# HDSC_HC32L130F8UA register map
Vendor: HDSC Co.Ltd; Series: ARMCM0P; File version: 1.2
CPU: CM0 r0p0, little endian, no MPU, no FPU, 3 interrupt priority bits
Registers are 32-bit, read-write, reset 0x0 unless marked. A register's access mark holds for its fields unless they carry their own. Offsets are from the block's base; [hi:lo] are bit positions; {n}, {i} and the like mark numbered series; 'fields as' and 'values as' point back to an identical list.

## TIM0_MODE23
Base 0x40000C00; alternate view of TIM0_MODE0
0x00 ARR
  [15:0] ARR
0x04 CNT
  [15:0] CNT
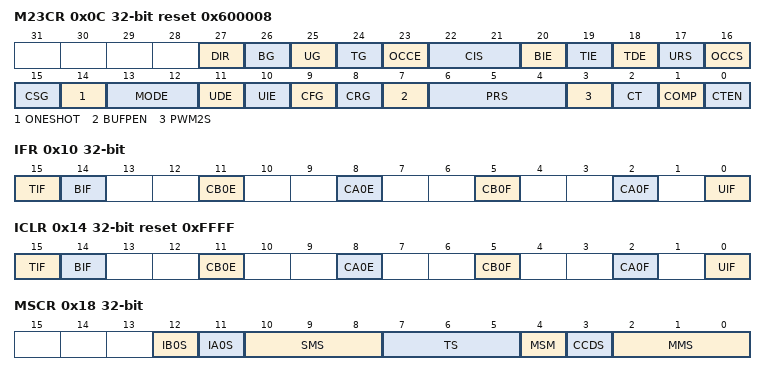
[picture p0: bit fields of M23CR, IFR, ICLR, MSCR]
0x0C M23CR reset 0x600008
  [27] DIR, [26] BG wo, [25] UG wo, [24] TG wo, [23] OCCE, [22:21] CIS, [20] BIE, [19] TIE, [18] TDE, [17] URS, [16] OCCS, [15] CSG, [14] ONESHOT, [13:12] MODE, [11] UDE, [10] UIE, [9] CFG, [8] CRG, [7] BUFPEN, [6:4] PRS, [3] PWM2S, [2] CT, [1] COMP, [0] CTEN
0x10 IFR ro
  [15] TIF, [14] BIF, [11] CB0E, [8] CA0E, [5] CB0F, [2] CA0F, [0] UIF
0x14 ICLR wo reset 0xFFFF
  [15] TIF, [14] BIF, [11] CB0E, [8] CA0E, [5] CB0F, [2] CA0F, [0] UIF
0x18 MSCR
  [12] IB0S, [11] IA0S, [10:8] SMS, [7:5] TS, [4] MSM, [3] CCDS, [2:0] MMS
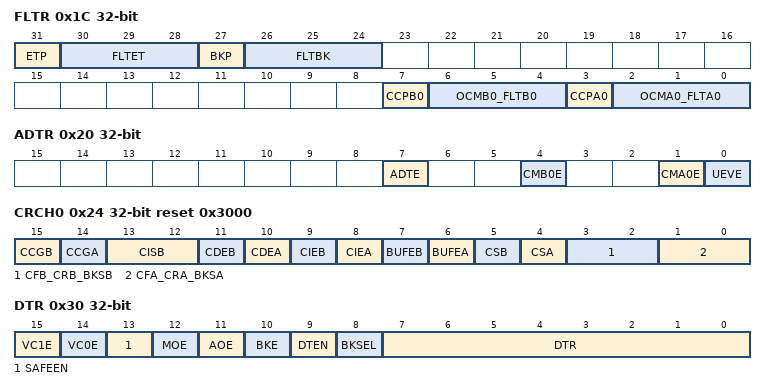
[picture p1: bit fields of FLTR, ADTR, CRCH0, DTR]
0x1C FLTR
  [31] ETP, [30:28] FLTET, [27] BKP, [26:24] FLTBK, [7] CCPB0, [6:4] OCMB0_FLTB0, [3] CCPA0, [2:0] OCMA0_FLTA0
0x20 ADTR
  [7] ADTE, [4] CMB0E, [1] CMA0E, [0] UEVE
0x24 CRCH0 reset 0x3000
  [15] CCGB, [14] CCGA, [13:12] CISB, [11] CDEB, [10] CDEA, [9] CIEB, [8] CIEA, [7] BUFEB, [6] BUFEA, [5] CSB, [4] CSA, [3:2] CFB_CRB_BKSB, [1:0] CFA_CRA_BKSA
0x30 DTR
  [15] VC1E, [14] VC0E, [13] SAFEEN, [12] MOE, [11] AOE, [10] BKE, [9] DTEN, [8] BKSEL, [7:0] DTR
0x34 RCR
  [7:0] RCR
0x38 ARRDM
  [15:0] ARRDM
0x3C CCR0A
  [15:0] CCR0A
0x40 CCR0B
  [15:0] CCR0B

## TIM1_MODE23
Base 0x40000D00; alternate view of TIM1_MODE0
Registers as TIM0_MODE23.

## TIM2_MODE23
Base 0x40000E00; alternate view of TIM2_MODE0
Registers as TIM0_MODE23.

## TIM3_MODE23
Base 0x40005800; alternate view of TIM3_MODE0
0x00 ARR
  [15:0] ARR
0x04 CNT
  [15:0] CNT
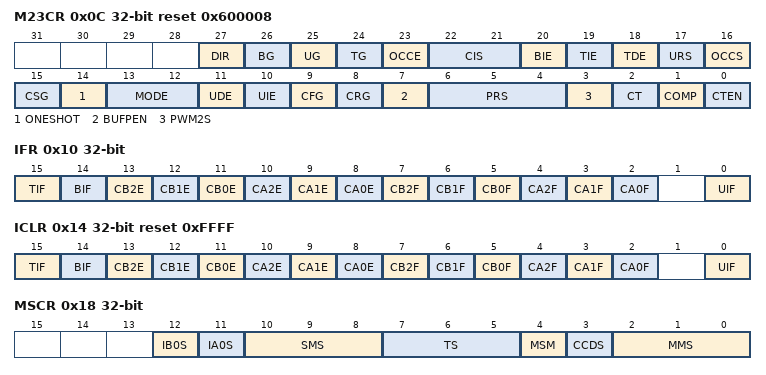
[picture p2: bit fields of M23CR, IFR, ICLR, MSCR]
0x0C M23CR reset 0x600008
  [27] DIR, [26] BG wo, [25] UG wo, [24] TG wo, [23] OCCE, [22:21] CIS, [20] BIE, [19] TIE, [18] TDE, [17] URS, [16] OCCS, [15] CSG, [14] ONESHOT, [13:12] MODE, [11] UDE, [10] UIE, [9] CFG, [8] CRG, [7] BUFPEN, [6:4] PRS, [3] PWM2S, [2] CT, [1] COMP, [0] CTEN
0x10 IFR ro
  [15] TIF, [14] BIF, [13] CB2E, [12] CB1E, [11] CB0E, [10] CA2E, [9] CA1E, [8] CA0E, [7] CB2F, [6] CB1F, [5] CB0F, [4] CA2F, [3] CA1F, [2] CA0F, [0] UIF
0x14 ICLR wo reset 0xFFFF
  fields as IFR
0x18 MSCR
  [12] IB0S, [11] IA0S, [10:8] SMS, [7:5] TS, [4] MSM, [3] CCDS, [2:0] MMS
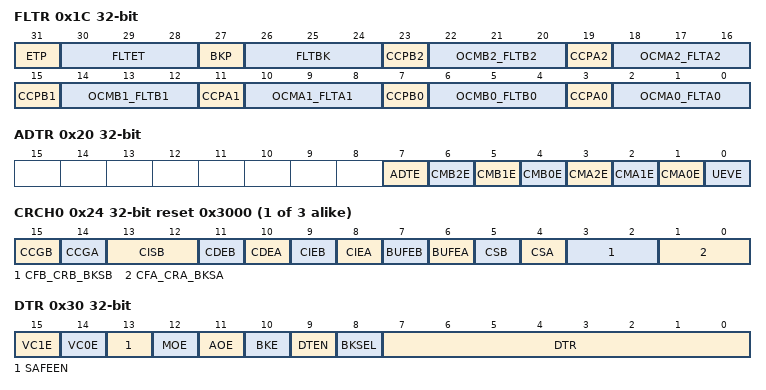
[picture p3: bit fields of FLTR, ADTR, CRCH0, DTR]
0x1C FLTR
  [31] ETP, [30:28] FLTET, [27] BKP, [26:24] FLTBK, [23] CCPB2, [22:20] OCMB2_FLTB2, [19] CCPA2, [18:16] OCMA2_FLTA2, [15] CCPB1, [14:12] OCMB1_FLTB1, [11] CCPA1, [10:8] OCMA1_FLTA1, [7] CCPB0, [6:4] OCMB0_FLTB0, [3] CCPA0, [2:0] OCMA0_FLTA0
0x20 ADTR
  [7] ADTE, [6] CMB2E, [5] CMB1E, [4] CMB0E, [3] CMA2E, [2] CMA1E, [1] CMA0E, [0] UEVE
{0x24+4i} CRCH{i} reset 0x3000 (i=0..2)
  [15] CCGB, [14] CCGA, [13:12] CISB, [11] CDEB, [10] CDEA, [9] CIEB, [8] CIEA, [7] BUFEB, [6] BUFEA, [5] CSB, [4] CSA, [3:2] CFB_CRB_BKSB, [1:0] CFA_CRA_BKSA
0x30 DTR
  [15] VC1E, [14] VC0E, [13] SAFEEN, [12] MOE, [11] AOE, [10] BKE, [9] DTEN, [8] BKSEL, [7:0] DTR
0x34 RCR
  [7:0] RCR
0x38 ARRDM
  [15:0] ARRDM
{0x3C+8i} CCR{i}A (i=0..2)
  [15:0] CCR{i}A
{0x40+8i} CCR{i}B (i=0..2)
  [15:0] CCR{i}B

## TIM4
Base 0x40003000
Same registers: TIM5 0x40003400, TIM6 0x40003800
0x00 CNTER
  [15:0] CNT
0x04 PERAR reset 0xFFFF
  [15:0] PERA
0x08 PERBR reset 0xFFFF
  [15:0] PERB
0x10 GCMAR reset 0xFFFF
  [15:0] GCMA
0x14 GCMBR reset 0xFFFF
  [15:0] GCMB
0x18 GCMCR reset 0xFFFF
  [15:0] GCMC
0x1C GCMDR reset 0xFFFF
  [15:0] GCMD
0x28 SCMAR reset 0xFFFF
  [15:0] SCMA
0x2C SCMBR reset 0xFFFF
  [15:0] SCMB
0x40 DTUAR reset 0xFFFF
  [15:0] DTUA
0x44 DTDAR reset 0xFFFF
  [15:0] DTDA
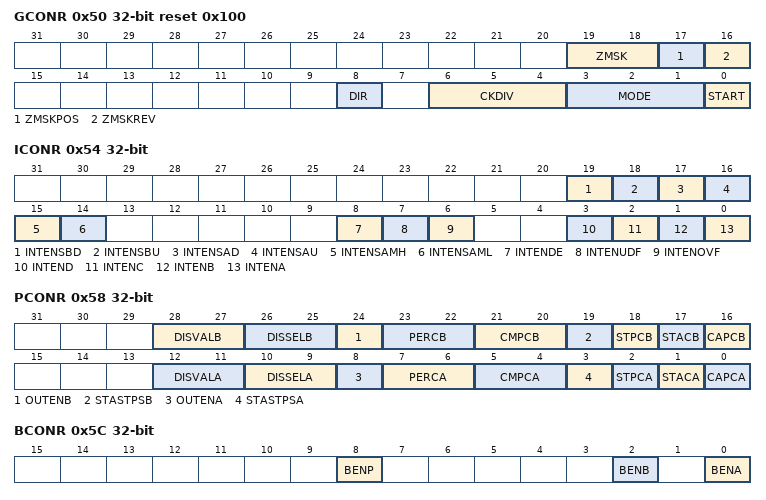
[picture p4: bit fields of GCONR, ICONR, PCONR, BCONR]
0x50 GCONR reset 0x100
  [19:18] ZMSK, [17] ZMSKPOS, [16] ZMSKREV, [8] DIR, [6:4] CKDIV, [3:1] MODE, [0] START
0x54 ICONR
  [19] INTENSBD, [18] INTENSBU, [17] INTENSAD, [16] INTENSAU, [15] INTENSAMH, [14] INTENSAML, [8] INTENDE, [7] INTENUDF, [6] INTENOVF, [3] INTEND, [2] INTENC, [1] INTENB, [0] INTENA
0x58 PCONR
  [28:27] DISVALB, [26:25] DISSELB, [24] OUTENB, [23:22] PERCB, [21:20] CMPCB, [19] STASTPSB, [18] STPCB, [17] STACB, [16] CAPCB, [12:11] DISVALA, [10:9] DISSELA, [8] OUTENA, [7:6] PERCA, [5:4] CMPCA, [3] STASTPSA, [2] STPCA, [1] STACA, [0] CAPCA
0x5C BCONR
  [8] BENP, [2] BENB, [0] BENA
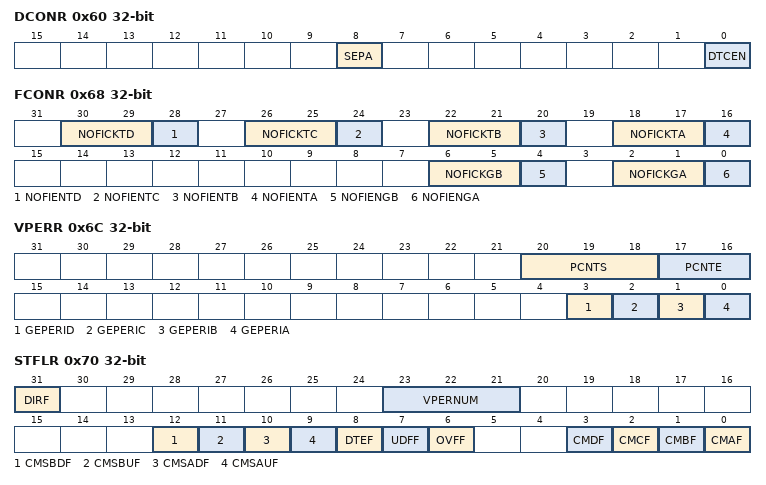
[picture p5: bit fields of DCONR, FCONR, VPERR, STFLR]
0x60 DCONR
  [8] SEPA, [0] DTCEN
0x68 FCONR
  [30:29] NOFICKTD, [28] NOFIENTD, [26:25] NOFICKTC, [24] NOFIENTC, [22:21] NOFICKTB, [20] NOFIENTB, [18:17] NOFICKTA, [16] NOFIENTA, [6:5] NOFICKGB, [4] NOFIENGB, [2:1] NOFICKGA, [0] NOFIENGA
0x6C VPERR
  [20:18] PCNTS, [17:16] PCNTE, [3] GEPERID, [2] GEPERIC, [1] GEPERIB, [0] GEPERIA
0x70 STFLR (reset mask 0x81C01FCF)
  [31] DIRF ro, [23:21] VPERNUM ro, [12] CMSBDF, [11] CMSBUF, [10] CMSADF, [9] CMSAUF, [8] DTEF, [7] UDFF, [6] OVFF, [3] CMDF, [2] CMCF, [1] CMBF, [0] CMAF
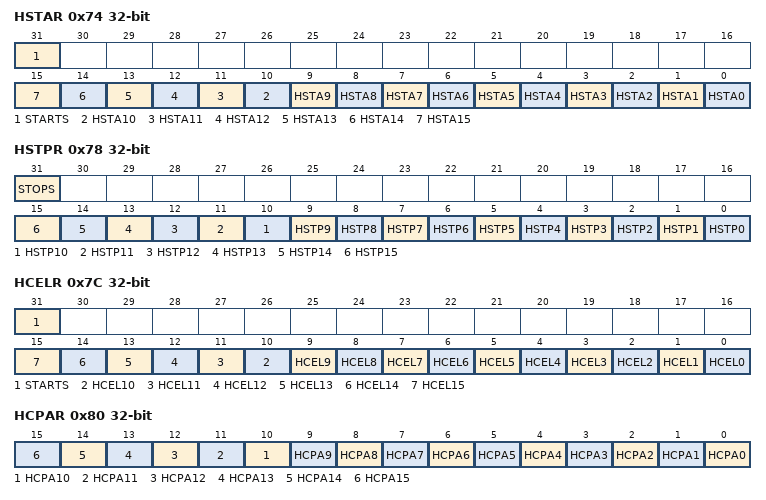
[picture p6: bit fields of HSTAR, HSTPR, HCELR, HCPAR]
0x74 HSTAR
  [31] STARTS, [n] HSTA{n} (n=0..15)
0x78 HSTPR
  [31] STOPS, [n] HSTP{n} (n=0..15)
0x7C HCELR
  [31] STARTS, [n] HCEL{n} (n=0..15)
0x80 HCPAR
  [n] HCPA{n} (n=0..15)
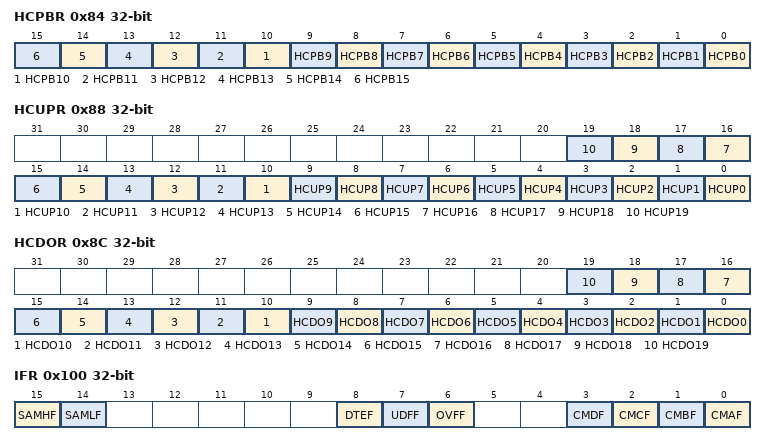
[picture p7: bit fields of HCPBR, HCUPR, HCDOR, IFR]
0x84 HCPBR
  [n] HCPB{n} (n=0..15)
0x88 HCUPR
  [n] HCUP{n} (n=0..19)
0x8C HCDOR
  [n] HCDO{n} (n=0..19)
0x100 IFR ro
  [15] SAMHF, [14] SAMLF, [8] DTEF, [7] UDFF, [6] OVFF, [3] CMDF, [2] CMCF, [1] CMBF, [0] CMAF
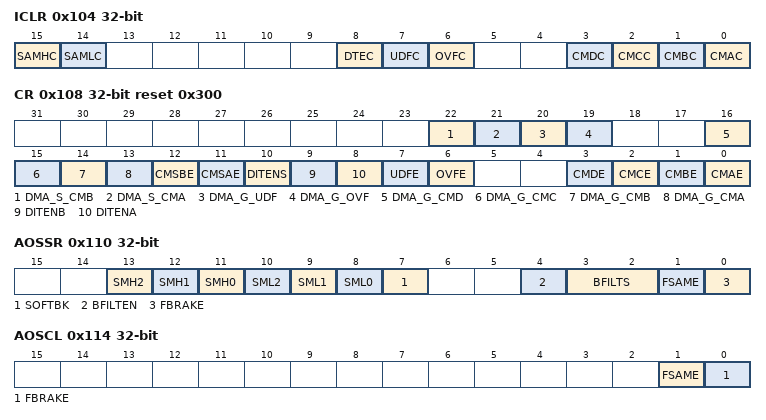
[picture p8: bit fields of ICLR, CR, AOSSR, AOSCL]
0x104 ICLR wo
  [15] SAMHC, [14] SAMLC, [8] DTEC, [7] UDFC, [6] OVFC, [3] CMDC, [2] CMCC, [1] CMBC, [0] CMAC
0x108 CR reset 0x300
  [22] DMA_S_CMB, [21] DMA_S_CMA, [20] DMA_G_UDF, [19] DMA_G_OVF, [16] DMA_G_CMD, [15] DMA_G_CMC, [14] DMA_G_CMB, [13] DMA_G_CMA, [12] CMSBE, [11] CMSAE, [10] DITENS, [9] DITENB, [8] DITENA, [7] UDFE, [6] OVFE, [3] CMDE, [2] CMCE, [1] CMBE, [0] CMAE
0x110 AOSSR
  [13] SMH2, [12] SMH1, [11] SMH0, [10] SML2, [9] SML1, [8] SML0, [7] SOFTBK, [4] BFILTEN, [3:2] BFILTS, [1] FSAME ro, [0] FBRAKE ro
0x114 AOSCL wo
  [1] FSAME, [0] FBRAKE
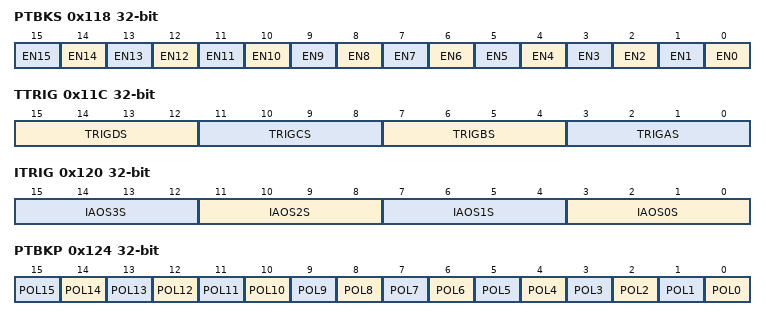
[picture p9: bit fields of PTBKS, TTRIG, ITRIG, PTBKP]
0x118 PTBKS
  [n] EN{n} (n=0..15)
0x11C TTRIG
  [15:12] TRIGDS, [11:8] TRIGCS, [7:4] TRIGBS, [3:0] TRIGAS
0x120 ITRIG
  [4n+3:4n] IAOS{n}S (n=0..3)
0x124 PTBKP
  [n] POL{n} (n=0..15)
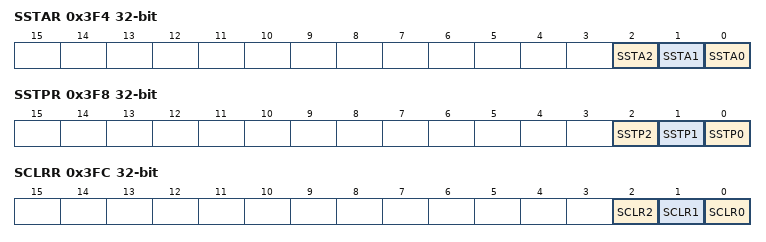
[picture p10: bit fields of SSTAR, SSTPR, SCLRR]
0x3F4 SSTAR
  [2] SSTA2, [1] SSTA1, [0] SSTA0
0x3F8 SSTPR
  [2] SSTP2, [1] SSTP1, [0] SSTP0
0x3FC SCLRR
  [2] SCLR2, [1] SCLR1, [0] SCLR0

## VC
Base 0x40002400; alternate view of ADC
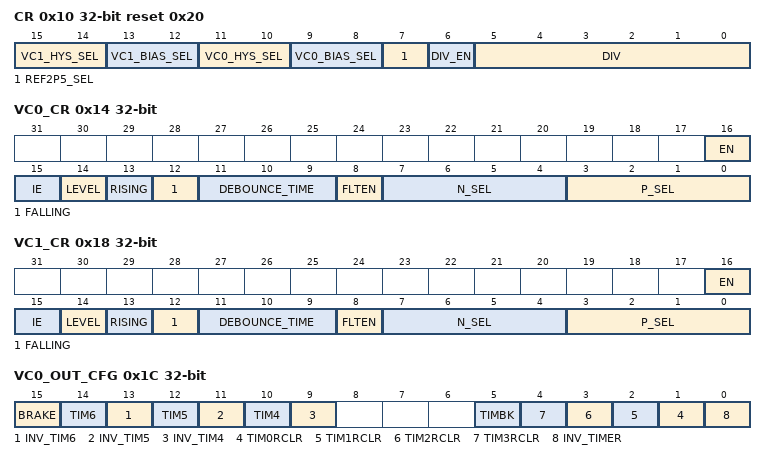
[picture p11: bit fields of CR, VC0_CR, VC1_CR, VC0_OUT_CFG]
0x10 CR reset 0x20
  [15:14] VC1_HYS_SEL, [13:12] VC1_BIAS_SEL, [11:10] VC0_HYS_SEL, [9:8] VC0_BIAS_SEL, [7] REF2P5_SEL, [6] DIV_EN, [5:0] DIV
0x14 VC0_CR
  [16] EN, [15] IE, [14] LEVEL, [13] RISING, [12] FALLING, [11:9] DEBOUNCE_TIME, [8] FLTEN, [7:4] N_SEL, [3:0] P_SEL
0x18 VC1_CR
  fields as VC0_CR
0x1C VC0_OUT_CFG
  [15] BRAKE, [14] TIM6, [13] INV_TIM6, [12] TIM5, [11] INV_TIM5, [10] TIM4, [9] INV_TIM4, [5] TIMBK, [n+1] TIM{n}RCLR (n=0..3), [0] INV_TIMER
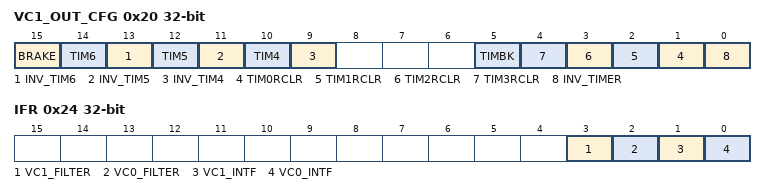
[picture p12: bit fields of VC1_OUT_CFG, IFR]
0x20 VC1_OUT_CFG
  fields as VC0_OUT_CFG
0x24 IFR
  [3] VC1_FILTER ro, [2] VC0_FILTER ro, [1] VC1_INTF, [0] VC0_INTF

## WDT
Base 0x40000F00; alternate view of LPTIMER
0x80 RST wo
  [7:0] RST
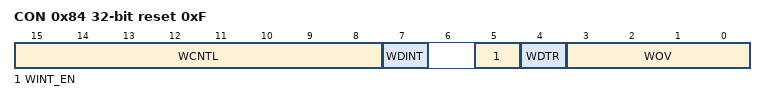
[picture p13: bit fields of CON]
0x84 CON reset 0xF
  [15:8] WCNTL ro, [7] WDINT ro, [5] WINT_EN, [4] WDTR ro, [3:0] WOV
